# ATSAMC20N17A register map
Vendor: Atmel Corporation; Series: SAMC20; File version: A
CPU: CM0+ r0p1, little endian, MPU, no FPU, VTOR, 2 interrupt priority bits
Registers are 32-bit, read-write, reset 0x0 unless marked. A register's access mark holds for its fields unless they carry their own. Offsets are from the block's base; [hi:lo] are bit positions; {n}, {i} and the like mark numbered series; 'fields as' and 'values as' point back to an identical list.

## TAL — Trigger Allocator
Base 0x42006000; register names take the prefix TAL_
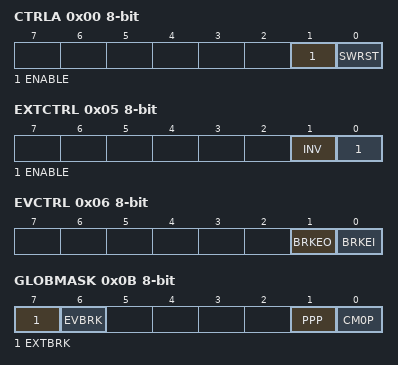
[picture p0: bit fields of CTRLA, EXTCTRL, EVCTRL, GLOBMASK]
0x00 CTRLA 8-bit — Control A
  [1] ENABLE
  [0] SWRST — Software Reset
0x04 RSTCTRL 8-bit — Reset Control
0x05 EXTCTRL 8-bit — External Break Control
  [1] INV — Invert BRK Pin
  [0] ENABLE — Enable BRK Pin
0x06 EVCTRL 8-bit — Event Control
  [1] BRKEO — Break Output Event Enable
  [0] BRKEI — Break Input Event Enable
0x08 INTENCLR 8-bit — Interrupt Enable Clear
  [0] BRK — Break Interrupt Enable
0x09 INTENSET 8-bit — Interrupt Enable Set
  [0] BRK — Break Interrupt Enable
0x0A INTFLAG 8-bit — Interrupt Flag Status and Clear
  [0] BRK — Break
0x0B GLOBMASK 8-bit — Global Break Requests Mask
  [7] EXTBRK — External Break Master
  [6] EVBRK — Event Break Master
  [1] PPP — PPP Break Master
  [0] CM0P — CM0P Break Master
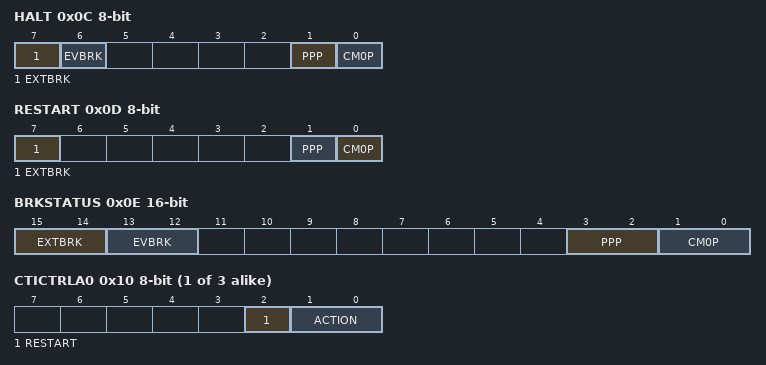
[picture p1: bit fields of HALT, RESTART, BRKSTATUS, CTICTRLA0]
0x0C HALT 8-bit wo — Debug Halt Request
  fields as GLOBMASK
0x0D RESTART 8-bit wo — Debug Restart Request
  [7] EXTBRK — External Break Master
  [1] PPP — PPP Break Master
  [0] CM0P — CM0P Break Master
0x0E BRKSTATUS 16-bit ro — Break Request Status
  [15:14] EXTBRK — External Break Request
    0=INT_RUN (External CPU running, by internal request); 1=INT_HALT (External CPU halted, by internal request); 2=EXT_RUN (External CPU running, by external request); 3=EXT_HALT (External CPU halted, by external request)
  [13:12] EVBRK — Event Break Request
    0=INT_RUN (EVBRK running)
  [3:2] PPP — PPP Break Request
    0=INT_RUN (PPP running, by internal request); 1=INT_HALT (PPP halted, by internal request); 2=EXT_RUN (PPP running, by external request); 3=EXT_HALT (PPP halted, by external request)
  [1:0] CM0P — CM0P Break Request
    0=INT_RUN (CM0P running, by internal request); 1=INT_HALT (CM0P halted, by internal request); 2=EXT_RUN (CM0P running, by external request); 3=EXT_HALT (CM0P halted, by external request)
{0x10+2i} CTICTRLA{i} (i=0..2) 8-bit — Cross-Trigger Interface n Control A
  [2] RESTART — Action when global restart issued
  [1:0] ACTION — Action when global break issued
    0=BREAK (Break when requested); 1=INTERRUPT (Trigger DBG interrupt instead of break); 2=IGNORE (Ignore break request)
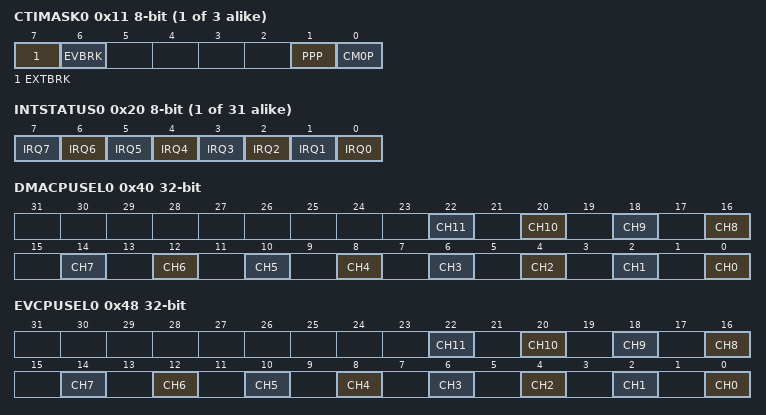
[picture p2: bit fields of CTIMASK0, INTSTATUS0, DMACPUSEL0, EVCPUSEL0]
{0x11+2i} CTIMASK{i} (i=0..2) 8-bit — Cross-Trigger Interface n Mask
  fields as GLOBMASK
{0x20+i} INTSTATUS{i} (i=0..30) 8-bit ro — Interrupt n Status
  [n] IRQ{n} (n=0..7) — Interrupt Status for Interrupt Request {n} within Interrupt n
0x40 DMACPUSEL0 — DMA Channel Interrupts CPU Select 0
  [2n] CH{n} (n=0..11) — DMA Channel {n} Interrupt CPU Select
0x48 EVCPUSEL0 — EVSYS Channel Interrupts CPU Select 0
  [2n] CH{n} (n=0..11) — Event Channel {n} Interrupt CPU Select
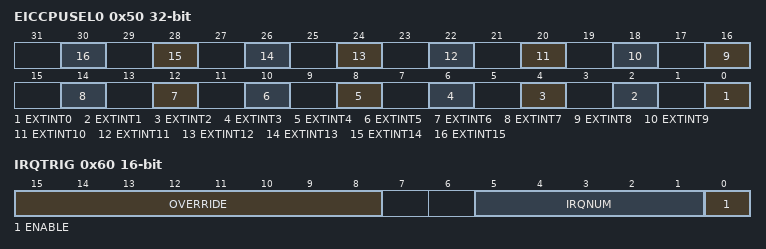
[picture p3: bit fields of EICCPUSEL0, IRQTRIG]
0x50 EICCPUSEL0 — EIC External Interrupts CPU Select 0
  [2n] EXTINT{n} (n=0..15) — External Interrupt {n} CPU Select
0x58 INTCPUSEL0 — Interrupts CPU Select 0
0x5C INTCPUSEL1 — Interrupts CPU Select 1
0x60 IRQTRIG 16-bit — Interrupt Trigger
  [15:8] OVERRIDE — Interrupt Request Override Value
  [5:1] IRQNUM — Interrupt Request Number
  [0] ENABLE — Trigger Enable

## WDT — Watchdog Timer
Base 0x40002000; register names take the prefix WDT_
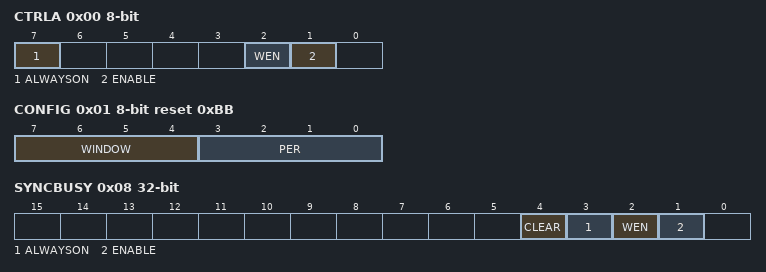
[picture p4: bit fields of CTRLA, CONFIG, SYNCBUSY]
0x00 CTRLA 8-bit — Control
  [7] ALWAYSON
  [2] WEN — Watchdog Timer Window Mode Enable
  [1] ENABLE
0x01 CONFIG 8-bit reset 0xBB — Configuration
  [7:4] WINDOW — Window Mode Time-Out Period
    0=CYC8 (8 clock cycles); 1=CYC16 (16 clock cycles); 2=CYC32 (32 clock cycles); 3=CYC64 (64 clock cycles); 4=CYC128 (128 clock cycles); 5=CYC256 (256 clock cycles); 6=CYC512 (512 clock cycles); 7=CYC1024 (1024 clock cycles); 8=CYC2048 (2048 clock cycles); 9=CYC4096 (4096 clock cycles); 10=CYC8192 (8192 clock cycles); 11=CYC16384 (16384 clock cycles)
  [3:0] PER — Time-Out Period
    values as WINDOW
0x02 EWCTRL 8-bit reset 0xB — Early Warning Interrupt Control
  [3:0] EWOFFSET — Early Warning Interrupt Time Offset
    values as CONFIG.WINDOW
0x04 INTENCLR 8-bit — Interrupt Enable Clear
  [0] EW — Early Warning Interrupt Enable
0x05 INTENSET 8-bit — Interrupt Enable Set
  [0] EW — Early Warning Interrupt Enable
0x06 INTFLAG 8-bit — Interrupt Flag Status and Clear
  [0] EW — Early Warning
0x08 SYNCBUSY ro — Synchronization Busy
  [4] CLEAR — Clear Busy
  [3] ALWAYSON — Always-On Busy
  [2] WEN — Window Enable Busy
  [1] ENABLE — Enable Busy
0x0C CLEAR 8-bit wo
  [7:0] CLEAR — Watchdog Clear
    165=KEY (Clear Key)

## Notices in the file
Atmel Microcontroller Software Support
Copyright (c) 2017 Atmel Corporation,
a wholly owned subsidiary of Microchip Technology Inc.
Licensed under the Apache License, Version 2.0 (the "License");
you may not use this file except in compliance with the License.
You may obtain a copy of the Licence at
http://www.apache.org/licenses/LICENSE-2.0
Unless required by applicable law or agreed to in writing, software
distributed under the License is distributed on an "AS IS" BASIS,
WITHOUT WARRANTIES OR CONDITIONS OF ANY KIND, either express or implied.
See the License for the specific language governing permissions and
limitations under the License.
